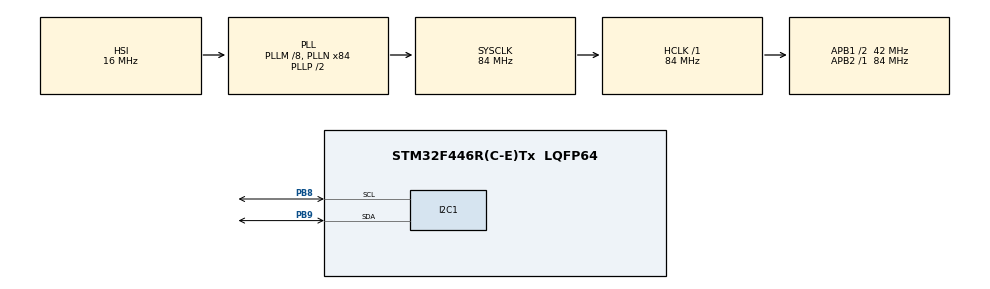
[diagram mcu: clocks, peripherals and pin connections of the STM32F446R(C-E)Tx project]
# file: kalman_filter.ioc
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Mcu.Family=STM32F4
Mcu.Name=STM32F446R(C-E)Tx
Mcu.Package=LQFP64
NVIC.PriorityGroup=NVIC_PRIORITYGROUP_4
NVIC.TIM3_IRQn=true\:0\:0\:false\:false\:true\:true\:true\:true
PA13.Mode=Trace_Asynchronous_SW
PA13.Signal=SYS_JTMS-SWDIO
PA14.Mode=Trace_Asynchronous_SW
PA14.Signal=SYS_JTCK-SWCLK
PB3.Mode=Trace_Asynchronous_SW
PB3.Signal=SYS_JTDO-SWO
PB8.GPIO_Pu=GPIO_PULLUP
PB8.Mode=I2C
PB8.Signal=I2C1_SCL
PB9.GPIO_Pu=GPIO_PULLUP
PB9.Mode=I2C
PB9.Signal=I2C1_SDA
PH0-OSC_IN.Mode=HSE-External-Oscillator
PH0-OSC_IN.Signal=RCC_OSC_IN
PH1-OSC_OUT.Mode=HSE-External-Oscillator
PH1-OSC_OUT.Signal=RCC_OSC_OUT
ProjectManager.HeapSize=0x200
ProjectManager.StackSize=0x400
ProjectManager.TargetToolchain=STM32CubeIDE
RCC.AHBFreq_Value=84000000
RCC.APB1CLKDivider=RCC_HCLK_DIV2
RCC.APB1Freq_Value=42000000
RCC.APB1TimFreq_Value=84000000
RCC.APB2Freq_Value=84000000
RCC.APB2TimFreq_Value=84000000
RCC.CortexFreq_Value=84000000
RCC.HCLKFreq_Value=84000000
RCC.PLLM=8
RCC.PLLN=84
RCC.SYSCLKFreq_VALUE=84000000
RCC.SYSCLKSource=RCC_SYSCLKSOURCE_PLLCLK
RCC.USBFreq_Value=84000000
RCC.VCOOutputFreq_Value=168000000
TIM3.AutoReloadPreload=TIM_AUTORELOAD_PRELOAD_ENABLE
TIM3.Period=9999
TIM3.Prescaler=41
VP_TIM3_VS_ClockSourceINT.Mode=Internal
board=custom

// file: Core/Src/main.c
/* USER CODE BEGIN Header */
/**
  ******************************************************************************
  * @file           : main.c
  * @brief          : Main program body
  ******************************************************************************
  * @attention
  *
  * Copyright (c) 2024 STMicroelectronics.
  * All rights reserved.
  *
  * This software is licensed under terms that can be found in the LICENSE file
  * in the root directory of this software component.
  * If no LICENSE file comes with this software, it is provided AS-IS.
  *
  ******************************************************************************
  */
/* USER CODE END Header */
#include "main.h"
#include "i2c.h"
#include "tim.h"
#include "gpio.h"

/* USER CODE BEGIN Includes */
#include <stdio.h>
#include <stdint.h>
#include <math.h>
#include "mpu6050.h"
#include "kalman_filter.h"
#include "comp_filter.h"
/* USER CODE END Includes */

/* USER CODE BEGIN PV */
HAL_StatusTypeDef status;
extern Orientation or;
extern mpu_data data;
extern Kalman filter;
float pitch;
float new_angle;
float err;
extern float pitchBias;
/* USER CODE END PV */

void SystemClock_Config(void);

int main(void)
{

  /* MCU Configuration--------------------------------------------------------*/

  /* Reset of all peripherals, Initializes the Flash interface and the Systick. */
  HAL_Init();

  /* Configure the system clock */
  SystemClock_Config();

  /* Initialize all configured peripherals */
  MX_GPIO_Init();
  MX_I2C1_Init();
  MX_TIM3_Init();
  /* USER CODE BEGIN 2 */
  status = mpu6050_init();
  calculate_pitch_bias();
  Kalman_init(&filter);
  Kalman_setAngle(&filter, 0);
  HAL_TIM_Base_Start_IT(&htim3);
  /* USER CODE END 2 */

  /* Infinite loop */
  while (1)
  {

  }
}

void SystemClock_Config(void)
{
  RCC_OscInitTypeDef RCC_OscInitStruct = {0};
  RCC_ClkInitTypeDef RCC_ClkInitStruct = {0};

  /** Configure the main internal regulator output voltage
  */
  __HAL_RCC_PWR_CLK_ENABLE();
  __HAL_PWR_VOLTAGESCALING_CONFIG(PWR_REGULATOR_VOLTAGE_SCALE3);

  /** Initializes the RCC Oscillators according to the specified parameters
  * in the RCC_OscInitTypeDef structure.
  */
  RCC_OscInitStruct.OscillatorType = RCC_OSCILLATORTYPE_HSI;
  RCC_OscInitStruct.HSIState = RCC_HSI_ON;
  RCC_OscInitStruct.HSICalibrationValue = RCC_HSICALIBRATION_DEFAULT;
  RCC_OscInitStruct.PLL.PLLState = RCC_PLL_ON;
  RCC_OscInitStruct.PLL.PLLSource = RCC_PLLSOURCE_HSI;
  RCC_OscInitStruct.PLL.PLLM = 8;
  RCC_OscInitStruct.PLL.PLLN = 84;
  RCC_OscInitStruct.PLL.PLLP = RCC_PLLP_DIV2;
  RCC_OscInitStruct.PLL.PLLQ = 2;
  RCC_OscInitStruct.PLL.PLLR = 2;
  if (HAL_RCC_OscConfig(&RCC_OscInitStruct) != HAL_OK)
  {
    Error_Handler();
  }

  /** Initializes the CPU, AHB and APB buses clocks
  */
  RCC_ClkInitStruct.ClockType = RCC_CLOCKTYPE_HCLK|RCC_CLOCKTYPE_SYSCLK
                              |RCC_CLOCKTYPE_PCLK1|RCC_CLOCKTYPE_PCLK2;
  RCC_ClkInitStruct.SYSCLKSource = RCC_SYSCLKSOURCE_PLLCLK;
  RCC_ClkInitStruct.AHBCLKDivider = RCC_SYSCLK_DIV1;
  RCC_ClkInitStruct.APB1CLKDivider = RCC_HCLK_DIV2;
  RCC_ClkInitStruct.APB2CLKDivider = RCC_HCLK_DIV1;

  if (HAL_RCC_ClockConfig(&RCC_ClkInitStruct, FLASH_LATENCY_2) != HAL_OK)
  {
    Error_Handler();
  }
}

/* USER CODE BEGIN 4 */
void HAL_TIM_PeriodElapsedCallback(TIM_HandleTypeDef *htim){
	if(htim -> Instance == TIM3){
		data = mpu6050_data();
		updateOrientation(data.ax, data.ay, data.az, data.gx, data.gy, data.gz);
		new_angle = atan(data.ax / sqrt(data.ay*data.ay + data.az*data.az)) * 180 / M_PI;
		pitch = Kalman_getAngle(&filter, new_angle, data.gx) - pitchBias;
		err = pitch - or.pitch;
	}
}
/* USER CODE END 4 */

void Error_Handler(void)
{
  __disable_irq();
  while (1)
  {
  }
}
